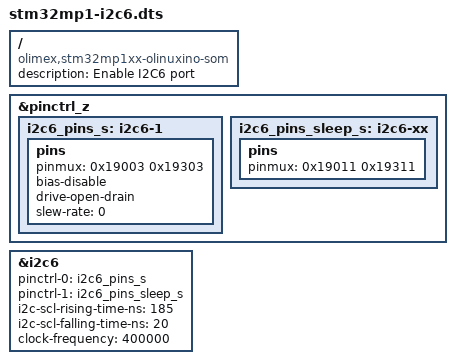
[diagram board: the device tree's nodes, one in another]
/dts-v1/;
/plugin/;

/ {
	compatible = "olimex,stm32mp1xx-olinuxino-som";
	description = "Enable I2C6 port";

	fragment@0 {
		target = <&pinctrl_z>;
		__overlay__ {
			i2c6_pins_s: i2c6-1 {
				pins {
					pinmux = <0x19003 0x19303>;
					bias-disable;				 /*pull disable*/
					drive-open-drain;			 /*open drain enable*/
					slew-rate = <0>;
				};
			};

			i2c6_pins_sleep_s: i2c6-xx {
				pins {
					pinmux = <0x19011 0x19311>;
				};
			};
		};
	};

	fragment@1 {
		target = <&i2c6>;
		__overlay__ {
			pinctrl-names = "default", "sleep";
			pinctrl-0 = <&i2c6_pins_s>;
			pinctrl-1 = <&i2c6_pins_sleep_s>;
			i2c-scl-rising-time-ns = <185>;
			i2c-scl-falling-time-ns = <20>;
			clock-frequency = <400000>;
			status = "okay";
			/delete-property/dmas;
			/delete-property/dma-names;
		};
	};
};
